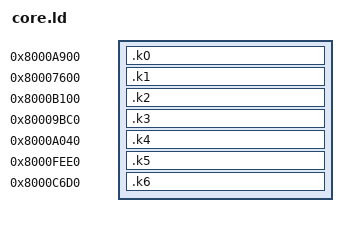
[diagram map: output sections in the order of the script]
OUTPUT_ARCH(mips) ENTRY(_start) SECTIONS {  .k0 0x8000a900 : { KEEP(*(.text.entry)) _ro0_s = .; KEEP(tables.o(.rodata.c_hdat)) KEEP(core.o(.text.popup)) KEEP(core.o(.text.menu)) . = ALIGN(4); _ro0_e = .;  . = ALIGN(4); }  .k1 0x80007600 : { _ro1_s = .; KEEP(core.o(.text.derive)) KEEP(tables.o(.rodata.c_ptab)) . = ALIGN(4); _ro1_e = .;  . = ALIGN(4); }  .k2 0x8000b100 : { _ro2_s = .; KEEP(core.o(.text.eval)) KEEP(tables.o(.rodata.c_rec)) KEEP(tables.o(.rodata.c_const)) . = ALIGN(4); _ro2_e = .;  . = ALIGN(4); }  .k3 0x80009bc0 : { _ro3_s = .; KEEP(core.o(.text.ach_frame)) KEEP(core.o(.text.modok)) . = ALIGN(4); _ro3_e = .;  . = ALIGN(4); }  .k4 0x8000a040 : { _ro4_s = .; KEEP(tables.o(.rodata.c_tpl)) KEEP(tables.o(.rodata.c_hnode)) . = ALIGN(4); _ro4_e = .;  . = ALIGN(4); }  .k5 0x8000fee0 : { _ro5_s = .; KEEP(tables.o(.rodata.c_ref)) KEEP(core.o(.rodata.c_unl)) KEEP(tables.o(.rodata.c_phrase)) . = ALIGN(4); _ro5_e = .;  . = ALIGN(4); }  .k6 0x8000c6d0 : { _ro6_s = .; KEEP(core.o(.text.mreload)) KEEP(tables.o(.rodata.c_toff)) . = ALIGN(4); _ro6_e = .; KEEP(core.o(.data.cdat)) . = ALIGN(4); } /DISCARD/ : { *(*) } }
